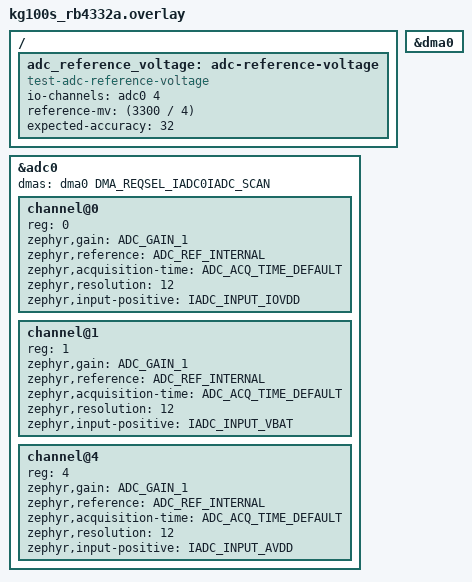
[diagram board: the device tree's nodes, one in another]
/*
 * Copyright (c) 2026 Martin Moya <martin.moya@focus.uy>
 *
 * SPDX-License-Identifier: Apache-2.0
 */

#include "dt-bindings/adc/silabs-adc.h"

&adc0 {
	status = "okay";
	#address-cells = <1>;
	#size-cells = <0>;

	channel@0 {
		reg = <0>;
		zephyr,gain = "ADC_GAIN_1";
		zephyr,reference = "ADC_REF_INTERNAL";
		zephyr,acquisition-time = <ADC_ACQ_TIME_DEFAULT>;
		zephyr,resolution = <12>;
		zephyr,input-positive = <IADC_INPUT_IOVDD>;
	};

	channel@1 {
		reg = <1>;
		zephyr,gain = "ADC_GAIN_1";
		zephyr,reference = "ADC_REF_INTERNAL";
		zephyr,acquisition-time = <ADC_ACQ_TIME_DEFAULT>;
		zephyr,resolution = <12>;
		zephyr,input-positive = <IADC_INPUT_VBAT>;
	};

	channel@4 {
		reg = <4>;
		zephyr,gain = "ADC_GAIN_1";
		zephyr,reference = "ADC_REF_INTERNAL";
		zephyr,acquisition-time = <ADC_ACQ_TIME_DEFAULT>;
		zephyr,resolution = <12>;
		zephyr,input-positive = <IADC_INPUT_AVDD>;
	};
};

&adc0 {
	dmas = <&dma0 DMA_REQSEL_IADC0IADC_SCAN>;
};

&dma0 {
	status = "okay";
};

/ {
	adc_reference_voltage: adc-reference-voltage {
		compatible = "test-adc-reference-voltage";
		io-channels = <&adc0 4>;
		reference-mv = <(3300 / 4)>;
		expected-accuracy = <32>;
	};
};
